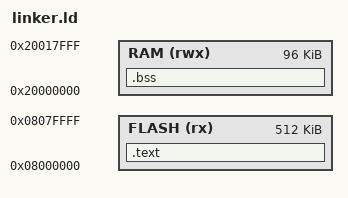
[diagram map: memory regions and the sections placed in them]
ENTRY(Reset_Handler)

MEMORY
{
  FLASH (rx)  : ORIGIN = 0x08000000, LENGTH = 512K
  RAM   (rwx) : ORIGIN = 0x20000000, LENGTH = 96K
}

SECTIONS
{
  .text : {
    KEEP(*(.isr_vector))
    *(.text*)
    *(.rodata*)
  } > FLASH

    .bss : {
        _sbss = .;
        *(.bss*)
        *(COMMON)
        _ebss = .;
    } > RAM

}
_estack = ORIGIN(RAM) + LENGTH(RAM); /* Top of stack */
